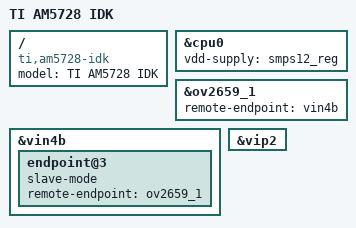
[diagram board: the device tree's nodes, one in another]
/*
 * Copyright (C) 2015-2016 Texas Instruments Incorporated - http://www.ti.com/
 *
 * This program is free software; you can redistribute it and/or modify
 * it under the terms of the GNU General Public License version 2 as
 * published by the Free Software Foundation.
 */

/dts-v1/;

#include "dra74x.dtsi"
#include "am572x-idk-common.dtsi"
#include "dra74x-mmc-iodelay.dtsi"

/ {
	model = "TI AM5728 IDK";
	compatible = "ti,am5728-idk", "ti,am5728", "ti,dra742", "ti,dra74",
		     "ti,dra7";
};

&cpu0 {
	vdd-supply = <&smps12_reg>;
};

&ov2659_1 {
	remote-endpoint = <&vin4b>;
};

&vin4b {
	status = "okay";

	endpoint@3 {
		slave-mode;
		remote-endpoint = <&ov2659_1>;
	};
};

&vip2 {
	status = "okay";
};
